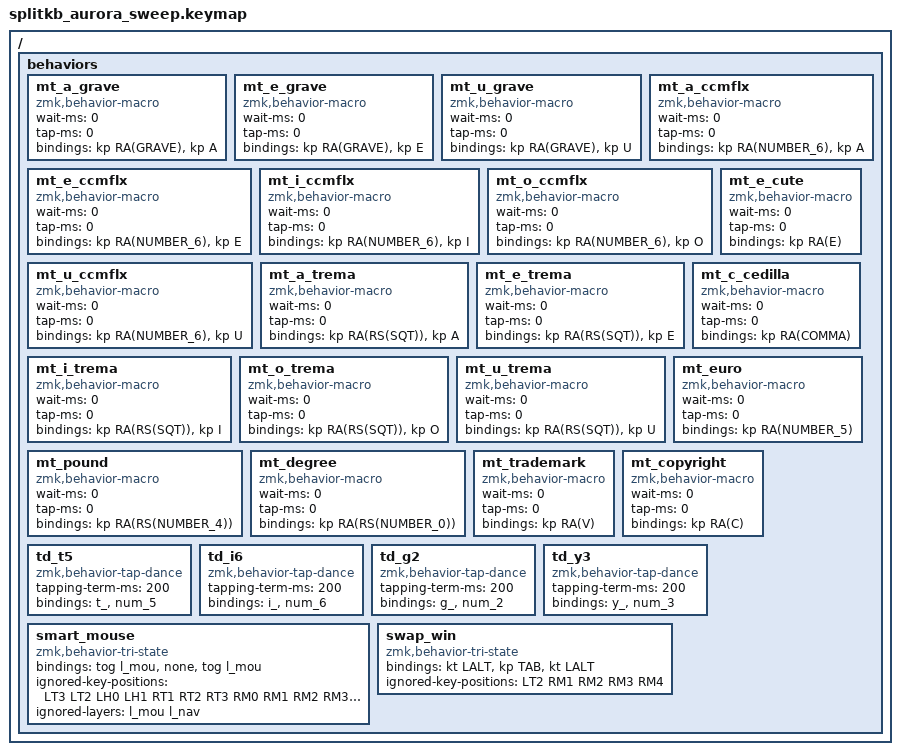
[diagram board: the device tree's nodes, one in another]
#include <behaviors.dtsi>
#include <dt-bindings/zmk/keys.h>
#include <dt-bindings/zmk/bt.h>
#include <dt-bindings/zmk/pointing.h>

#include "zmk-helpers/helper.h"
#include "zmk-helpers/key-labels/34.h"

#include "defines/main.h"
#include "macros/main.h"
#include "behaviors/main.h"
#include "layers/aurora_sweep/main.h"
#include "combos/main.h"

// dead-key sequences for a US-International host
ZMK_MACRO(mt_a_grave,   wait-ms = <0>; tap-ms = <0>; bindings = <&kp RA(GRAVE) &kp A>;)
ZMK_MACRO(mt_e_grave,   wait-ms = <0>; tap-ms = <0>; bindings = <&kp RA(GRAVE) &kp E>;)
ZMK_MACRO(mt_u_grave,   wait-ms = <0>; tap-ms = <0>; bindings = <&kp RA(GRAVE) &kp U>;)
ZMK_MACRO(mt_a_ccmflx,  wait-ms = <0>; tap-ms = <0>; bindings = <&kp RA(NUMBER_6) &kp A>;)
ZMK_MACRO(mt_e_ccmflx,  wait-ms = <0>; tap-ms = <0>; bindings = <&kp RA(NUMBER_6) &kp E>;)
ZMK_MACRO(mt_i_ccmflx,  wait-ms = <0>; tap-ms = <0>; bindings = <&kp RA(NUMBER_6) &kp I>;)
ZMK_MACRO(mt_o_ccmflx,  wait-ms = <0>; tap-ms = <0>; bindings = <&kp RA(NUMBER_6) &kp O>;)
ZMK_MACRO(mt_u_ccmflx,  wait-ms = <0>; tap-ms = <0>; bindings = <&kp RA(NUMBER_6) &kp U>;)
ZMK_MACRO(mt_a_trema,   wait-ms = <0>; tap-ms = <0>; bindings = <&kp RA(RS(SQT)) &kp A>;)
ZMK_MACRO(mt_e_trema,   wait-ms = <0>; tap-ms = <0>; bindings = <&kp RA(RS(SQT)) &kp E>;)
ZMK_MACRO(mt_i_trema,   wait-ms = <0>; tap-ms = <0>; bindings = <&kp RA(RS(SQT)) &kp I>;)
ZMK_MACRO(mt_o_trema,   wait-ms = <0>; tap-ms = <0>; bindings = <&kp RA(RS(SQT)) &kp O>;)
ZMK_MACRO(mt_u_trema,   wait-ms = <0>; tap-ms = <0>; bindings = <&kp RA(RS(SQT)) &kp U>;)
ZMK_MACRO(mt_e_cute,    wait-ms = <0>; tap-ms = <0>; bindings = <&kp RA(E)>;)
ZMK_MACRO(mt_c_cedilla, wait-ms = <0>; tap-ms = <0>; bindings = <&kp RA(COMMA)>;)
ZMK_MACRO(mt_euro,      wait-ms = <0>; tap-ms = <0>; bindings = <&kp RA(NUMBER_5)>;)
ZMK_MACRO(mt_pound,     wait-ms = <0>; tap-ms = <0>; bindings = <&kp RA(RS(NUMBER_4))>;)
ZMK_MACRO(mt_degree,    wait-ms = <0>; tap-ms = <0>; bindings = <&kp RA(RS(NUMBER_0))>;)
ZMK_MACRO(mt_trademark, wait-ms = <0>; tap-ms = <0>; bindings = <&kp RA(V)>;)
ZMK_MACRO(mt_copyright, wait-ms = <0>; tap-ms = <0>; bindings = <&kp RA(C)>;)

ZMK_TAP_DANCE(td_t5, tapping-term-ms = <200>; bindings = <t_>, <num_5>;)
ZMK_TAP_DANCE(td_i6, tapping-term-ms = <200>; bindings = <i_>, <num_6>;)
ZMK_TAP_DANCE(td_g2, tapping-term-ms = <200>; bindings = <g_>, <num_2>;)
ZMK_TAP_DANCE(td_y3, tapping-term-ms = <200>; bindings = <y_>, <num_3>;)

// toggles the mouse layer, auto-exits on any key outside it
ZMK_TRI_STATE(smart_mouse,
  bindings = <&tog l_mou>, <none>, <&tog l_mou>;
  ignored-key-positions = <LT3 LT2 LH0 LH1 RT1 RT2 RT3 RM0 RM1 RM2 RM3 RM4 RB1 RB2 RB3 RH0 RH1>;
  ignored-layers = <l_mou l_nav>;
)

// alt-tab window switcher, stays active while the nav layer drives it
ZMK_TRI_STATE(swap_win,
  bindings = <&kt LALT>, <&kp TAB>, <&kt LALT>;
  ignored-key-positions = <LT2 RM1 RM2 RM3 RM4>;
)

// the hardware layer has no key of its own: hold nav and fun together
ZMK_CONDITIONAL_LAYER(hardware, l_nav l_fun, l_har)
